# RL6845_IP_SVD register map
Vendor: Realtek
Registers are 32-bit, read-write, reset 0x0 unless marked. A register's access mark holds for its fields unless they carry their own. Offsets are from the block's base; [hi:lo] are bit positions; lines under a group give offsets from that group; {n}, {i} and the like mark numbered series.

## RXI300_REG
Base 0x41102000
Same registers: MPC1_S 0x51102200, MPC2_S 0x51102300, PPC_S 0x51102400
0x00 NAME ro reset 0x52300 — RXI300 design name register
  [31:0] NAME — The design name of RXI-300.
0x04 VER ro reset 0x300 — RXI300 design version register
  [31:0] VER — The design version of RXI-300.
0x08 RVE ro — RXI300 design reversion register
  [31:0] REV — The design reversion of RXI-300.
0x0C INST ro — RXI300 design instance number register
  [31:0] INST — The design instance number of RXI-300.
0x10 IMPL_Y ro reset 0x2022 — RXI300 implementation year register
  [31:0] IMPL_Y — The implementatin year of RXI-300. Reset value depends on implementation date.
0x14 IMPL_D ro reset 0x8081200 — RXI300 implementation date register
  [31:0] IMPL_D — The implementatin date of RXI-300. Reset value depends on implementation date.
0x18 DEV ro reset 0x5207583 — RXI300 developer register
  [31:0] DEV — The developer of RXI-300.
0x1C PRO_NUM ro reset 0x6920 — RXI300 project number register
  [31:0] PRO_NUM — The project number of RXI-300.
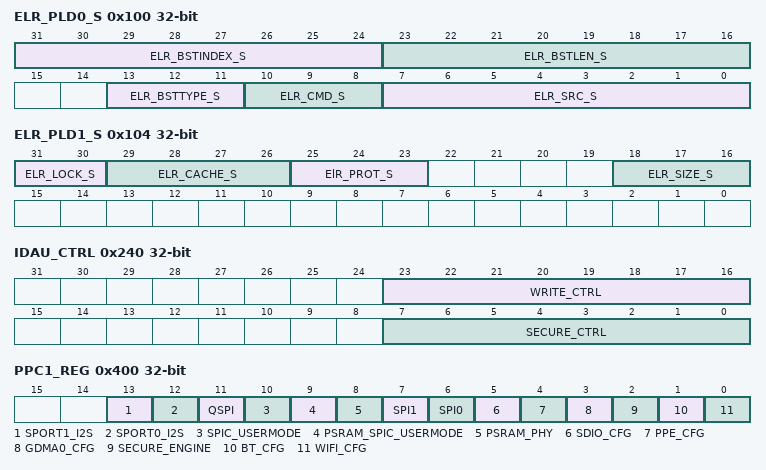
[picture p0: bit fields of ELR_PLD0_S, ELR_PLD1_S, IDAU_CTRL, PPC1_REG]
0x100 ELR_PLD0_S ro — Error log payload register
  [31:24] ELR_BSTINDEX_S — Burst index of the error request.
  [23:16] ELR_BSTLEN_S — Burst Length of the error request.
  [13:11] ELR_BSTTYPE_S — BurstSeq of the error request.
  [10:8] ELR_CMD_S — CMD of the error request. 0x1: Write command 0x2: Read command
  [7:0] ELR_SRC_S — Error source of the error request. 0x10: S0 group address hole default slave 0x11: S1, S2 group address hole default slave
0x104 ELR_PLD1_S ro — Error log payload register1
  [31:30] ELR_LOCK_S — AxLock of the error request.
  [29:26] ELR_CACHE_S — AxCache of the error request.
  [25:23] ElR_PROT_S — AxProt of the error request.
  [18:16] ELR_SIZE_S — Size of the error request.
0x108 ELR_ID_S ro — Error log tagid register
  [31:0] ELR_ID_S — Tagid of the error request. 9'b00000????: M0 access error 9'b00010????: M1 access error 9'b0010?????: M2 access error 9'b001100???: M3 access error 9'b01110000?: M4-0 access error 9'b01000000?: M4-1 access error 9'b01010000?: M5 access error 9'b01100000?: M6 access error
0x10C ELR_ADR0_S ro — Error log addrress register
  [31:0] ELR_ADR0_S — Address[31:0] of the error request.
0x110 ELR_ADR1_S ro — Error log addrress register1
  [31:0] ELR_ADR1_S — Address[63:32] of the error request.
0x130 ELR_CODE_S ro — Error log error code register
  [7:0] ELR_CODE_S — The error code of error request, if it's 0, indicates that there is no error request. 8'h00: No error 8'h01: Address hole error
0x13C ELR_INTR_CLR_S wo — Error log interrupt clear register
  [0] ELR_INTR_CLR_S — Error log interrupt clear. Writing 1'b1 to the register will trigger a 1-cycle pulse interrupt clear. It has to write 1'b1 to this register every time when the error excep-tion occurs. Note that this register is write-only, the return value of reading this register is meaningless.
{0x200+8i} IDAU_BA{i} (i=0..7) — IDAU base address register{i}
  [31:12] IDAU_BA{i} — It's the base address of region {i} which can be set as non-secure.
{0x204+8i} IDAU_LA{i} reset 0xFFFFF000 (i=0..7) — IDAU top address register{i}
  [31:12] IDAU_LA{i} — It's the top address of region {i} which can be set as non-secure. For IDAU_LA0, the default is FFFFF000h; for IDAU_LAx, the default is 00000000h.
0x240 IDAU_CTRL — IDAU enable control register
  [23:16] WRITE_CTRL — Write permission address control register. Bit[23]: controls entry 7. Bit[22]: controls entry 6. Bit[21]: controls entry 5. Bit[20]: controls entry 4. Bit[19]: controls entry 3. Bit[18]: controls entry 2. Bit[17]: controls entry 1. Bit[16]: controls entry 0. When the bit[x] is 1'b1, mask the address region as write forbidden attribution; when it is 1'b0, the address region is read/write attribution. Note: When the LOCK register is 1'b1, you cannot program this register unless system reset.
  [7:0] SECURE_CTRL — MPC secure address control register. Bit[7]: controls entry 7. Bit[6]: controls entry 6. Bit[5]: controls entry 5. Bit[4]: controls entry 4. Bit[3]: controls entry 3. Bit[2]: controls entry 2. Bit[1]: controls entry 1. Bit[0]: controls entry 0. When the bit[x] is 1'b1, mask the address region as non-secure attribution; when it is 1'b0, the address region is secure attribution. Note: When the LOCK register is 1'b1, you cannot program this register unless system reset.
0x244 IDAU_LOCK — IDAU lock control register
  [0] IDAU_LOCK — Lock write transfer for all registers in IDAU (including lock register it self) until system reset if it is ebabled. [0]: lock bit for all registers in IDAU 0: disable lock 1: enable lock
0x400 PPC1_REG — PPC1 control register
  [13] SPORT1_I2S — 1: Non-secure attribution 0: Secure attribution
  [12] SPORT0_I2S — 1: Non-secure attribution 0: Secure attribution
  [11] QSPI — 1: Non-secure attribution 0: Secure attribution
  [10] SPIC_USERMODE — 1: Non-secure attribution 0: Secure attribution
  [9] PSRAM_SPIC_USERMODE — 1: Non-secure attribution 0: Secure attribution
  [8] PSRAM_PHY — 1: Non-secure attribution 0: Secure attribution
  [7] SPI1 — 1: Non-secure attribution 0: Secure attribution
  [6] SPI0 — 1: Non-secure attribution 0: Secure attribution
  [5] SDIO_CFG — 1: Non-secure attribution 0: Secure attribution
  [4] PPE_CFG — 1: Non-secure attribution 0: Secure attribution
  [3] GDMA0_CFG — 1: Non-secure attribution 0: Secure attribution
  [2] SECURE_ENGINE — 1: Non-secure attribution 0: Secure attribution
  [1] BT_CFG — 1: Non-secure attribution 0: Secure attribution
  [0] WIFI_CFG — 1: Non-secure attribution 0: Secure attribution
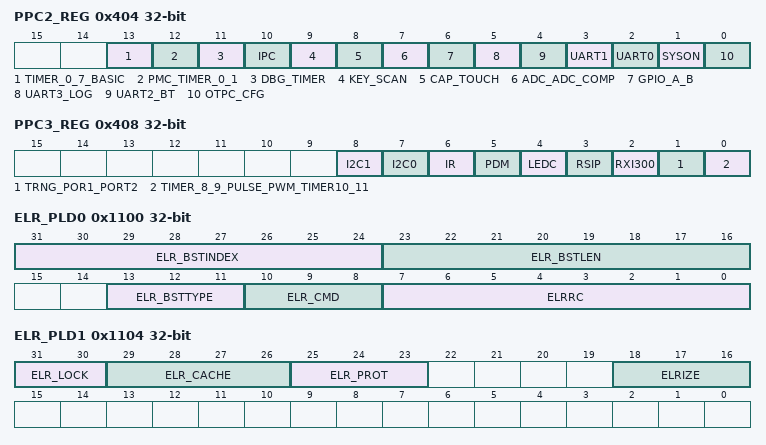
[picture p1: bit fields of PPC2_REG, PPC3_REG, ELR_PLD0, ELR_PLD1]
0x404 PPC2_REG — PPC2 control register
  [13] TIMER_0_7_BASIC — 1: Non-secure attribution 0: Secure attribution
  [12] PMC_TIMER_0_1 — 1: Non-secure attribution 0: Secure attribution
  [11] DBG_TIMER — 1: Non-secure attribution 0: Secure attribution
  [10] IPC — 1: Non-secure attribution 0: Secure attribution
  [9] KEY_SCAN — 1: Non-secure attribution 0: Secure attribution
  [8] CAP_TOUCH — 1: Non-secure attribution 0: Secure attribution
  [7] ADC_ADC_COMP — 1: Non-secure attribution 0: Secure attribution
  [6] GPIO_A_B — 1: Non-secure attribution 0: Secure attribution
  [5] UART3_LOG — 1: Non-secure attribution 0: Secure attribution
  [4] UART2_BT — 1: Non-secure attribution 0: Secure attribution
  [3] UART1 — 1: Non-secure attribution 0: Secure attribution
  [2] UART0 — 1: Non-secure attribution 0: Secure attribution
  [1] SYSON — 1: Non-secure attribution 0: Secure attribution
  [0] OTPC_CFG — 1: Non-secure attribution 0: Secure attribution
0x408 PPC3_REG — PPC3 control register
  [8] I2C1 — 1: Non-secure attribution 0: Secure attribution
  [7] I2C0 — 1: Non-secure attribution 0: Secure attribution
  [6] IR — 1: Non-secure attribution 0: Secure attribution
  [5] PDM — 1: Non-secure attribution 0: Secure attribution
  [4] LEDC — 1: Non-secure attribution 0: Secure attribution
  [3] RSIP — 1: Non-secure attribution 0: Secure attribution
  [2] RXI300 — 1: Non-secure attribution 0: Secure attribution
  [1] TRNG_POR1_PORT2 — 1: Non-secure attribution 0: Secure attribution
  [0] TIMER_8_9_PULSE_PWM_TIMER10_11 — 1: Non-secure attribution 0: Secure attribution
0x40C PPC_LOCK — PPC LOCK configure register
  [0] LOCK — PPC lock register. When writing 1'b1 to this nit, PPC will be locked. Note: It can not be written to 1'b0 again until system reset to prevent modification. When PPC is locked, you can not program PPC registers unless system reset.
0x1000 SPIC_ARB_CTRL0 — SPIC arbitration control register
  [31:0] SPIC_ARB_CTRL0 — Arbitration control register. The arbitration can flexibly set the priority of input port. The arbitration scheme of slots uses round-robin. User can use more slots to remap input ports request and define the order of slots. If one of requests has low-priority or low-bandwidth , maybe user can allocate less slots. Otherwise, user can allocate more slots. Each slot should be set by a port number. The port number represents a master group. The master group is shown as below: 0x0: KM4 0x1: KM0, GDMA0, WIFI, LX, SDIO 0x2: PPE And the following shows bit field of each slots: [3:0]: slot 0 of arbiter [7:4]: slot 1 of arbiter [11:8]: slot 2 of arbiter [15:12]: slot 3 of arbiter [19:16]: slot 4 of arbiter [23:20]: slot 5 of arbiter [27:24]: slot 6 of arbiter [31:28]: slot 7 of arbiter
0x1004 SPIC_ARB_CTRL1 — SPIC arbitration control register1
  [31:0] SPIC_ARB_CTRL1 — This is extended register of SPIC_ARB_CTRL0. [3:0]: slot 8 of arbiter [7:4]: slot 9 of arbiter [11:8]: slot 10 of arbiter [15:12]: slot 11 of arbiter [19:16]: slot 12 of arbiter [23:20]: slot 13 of arbiter [27:24]: slot 14 of arbiter [31:28]: slot 15 of arbiter
0x1008 HSRAM_ARB_CTRL0 — HSRAM arbitration control register
  [31:0] HSRAM_ARB_CTRL0 — Arbitration control register. The arbitration can flexibly set the priority of input port. The arbitration scheme of slots uses round-robin. User can use more slots to remap input ports request and define the order of slots. If one of requests has low-priority or low-bandwidth, maybe user can allocate less slots. Otherwise, user can allocate more slots. Each slot should be set by a port number. The port number represents a master group: 0x0: KM4 0x1: KM0, GDMA0, WIFI, LX, SDIO, SIC, OTPC And the following shows bit field of each slots: [3:0]: slot 0 of arbiter [7:4]: slot 1 of arbiter [11:8]: slot 2 of arbiter [15:12]: slot 3 of arbiter [19:16]: slot 4 of arbiter [23:20]: slot 5 of arbiter [27:24]: slot 6 of arbiter [31:28]: slot 7 of arbiter
0x100C HSRAM_ARB_CTRL1 — HSRAM arbitration control register1
  [31:0] HSRAM_ARB_CTRL1 — This is extended register of HSRAM_ARB_CTRL0. [3:0]: slot 8 of arbiter [7:4]: slot 9 of arbiter [11:8]: slot 10 of arbiter [15:12]: slot 11 of arbiter [19:16]: slot 12 of arbiter [23:20]: slot 13 of arbiter [27:24]: slot 14 of arbiter [31:28]: slot 15 of arbiter
0x1010 HPERI_ARB_CTRL0 — HPERI arbitration control register
  [31:0] HPERI_ARB_CTRL0 — Arbitration control register. The arbitration can flexibly set the priority of input port. The arbitration scheme of slots uses round-robin.User can use more slots to remap input ports request and define the order of slots. If one of requests has low-priority or low-bandwidth, maybe user can allocate less slots. Otherwise, user can allocate more slots. Each slot should be set by a port number. The port number represents a master group: 0x0: KM4 0x1: KM0 0x2: GDMA 0x3: SIC And the following shows bit field of each slots: [3:0]: slot 0 of arbiter [7:4]: slot 1 of arbiter [11:8]: slot 2 of arbiter [15:12]: slot 3 of arbiter [19:16]: slot 4 of arbiter [23:20]: slot 5 of arbiter [27:24]: slot 6 of arbiter [31:28]: slot 7 of arbiter
0x1014 HPERI_ARB_CTRL1 — HPERI arbitration control register1
  [31:0] HPERI_ARB_CTRL1 — This is extended register of HPERI_ARB_CTRL0 slot. [3:0]: slot 8 of arbiter [7:4]: slot 9 of arbiter [11:8]: slot 10 of arbiter [15:12]: slot 11 of arbiter [19:16]: slot 12 of arbiter [23:20]: slot 13 of arbiter [27:24]: slot 14 of arbiter [31:28]: slot 15 of arbiter
0x1018 PSRAM_ARB_CTRL0 — PSRAM arbitration control register0
  [31:0] PSRAM_ARB_CTRL0 — Arbitration control register. The arbitration can flexibly set the priority of input port.The arbitration scheme of slots uses round-robin. User can use more slots to remap input ports request and define the order of slots. If one of requests has low-priority or low-bandwidth, maybe user can allocate less slots. Otherwise, user can allocate more slots. Each slot should be set by a port number. The port number represents a master group: 0x0: KM4 0x1: KM0, GDMA0, WIFI, LX, SDIO, SIC, OTPC 0x2: PPE And the following shows bit field of each slots: [3:0]: slot 0 of arbiter [7:4]: slot 1 of arbiter [11:8]: slot 2 of arbiter [15:12]: slot 3 of arbiter [19:16]: slot 4 of arbiter [23:20]: slot 5 of arbiter [27:24]: slot 6 of arbiter [31:28]: slot 7 of arbiter
0x101C PSRAM_ARB_CTRL1 — PSRAM arbitration control register1
  [31:0] PSRAM_ARB_CTRL1 — This is extended register of PSRAM_ARB_CTRL0 slot. [3:0]: slot 8 of arbiter [7:4]: slot 9 of arbiter [11:8]: slot 10 of arbiter [15:12]: slot 11 of arbiter [19:16]: slot 12 of arbiter [23:20]: slot 13 of arbiter [27:24]: slot 14 of arbiter [31:28]: slot 15 of arbiter
0x1100 ELR_PLD0 ro — Error log payload register
  [31:24] ELR_BSTINDEX — Burst index of the error request.
  [23:16] ELR_BSTLEN — Burst Length of the error request.
  [13:11] ELR_BSTTYPE — BurstSeq of the error request.
  [10:8] ELR_CMD — CMD of the error request. 0x1: Write command 0x2: Read command
  [7:0] ELRRC — Error source of the error request. 0x00: M0 secure default slave 0x01: M1 secure default slave 0x02: M2 secure default slave 0x03: M3 secure default slave 0x04: M4 secure default slave 0x05: M5 secure default slave 0x06: M6 secure default slave 0x10: S0 secure default slave 0x20: S1, S2 secure default slave 0x21: S6 secure default slave 0x30: S3 AHB group secure default slave 0x31: S3 APB group secure default slave 0x32: S3-11 secure default slave 0x33: S3 AXI group secure default slave 0x34: S3-8, S3-9 secure default slave 0x40: S4 secure default slave 0x41: S5 secure default slave
0x1104 ELR_PLD1 ro — Error log payload register1
  [31:30] ELR_LOCK — AxLock of the error request.
  [29:26] ELR_CACHE — AxCache of the error request.
  [25:23] ELR_PROT — AxProt of the error request.
  [18:16] ELRIZE — Size of the error request.
0x1108 ELR_ID ro — Error log tagid register
  [31:0] ELR_ID — Tagid of the error request. 9'b00000????: M0 access error 9'b00010????: M1 access error 9'b0010?????: M2 access error 9'b001100???: M3 access error 9'b01110000?: M4-0 access error 9'b01000000?: M4-1 access error 9'b01010000?: M5 access error 9'b01100000?: M6 access error
0x110C ELR_ADR0 ro — Error log addrress register
  [31:0] ELR_ADR0 — Address[31:0] of the error request.
0x1110 ELR_ADR1 ro — Error log addrress register1
  [31:0] ELR_ADR1 — Address[63:32] of the error request.
0x1130 ELR_CODE ro — Error log error code register
  [7:0] ELR_CODE — The error code of error request, if it's 0, indicates that there is no error request. 8'h00: No error 8'h02: Secure fault error
0x113C ELR_INTR_CLR wo — Error log interrupt clear register
  [0] ELR_INTR_CLR — Error log interrupt clear. Writing 1'b1 to the register will trigger a 1-cycle pulse interrupt clear. It has to write l'b1 to this register every time when the error excep-tion occurs. Note that this register is write-only, the return value of reading this register is meaningless.
